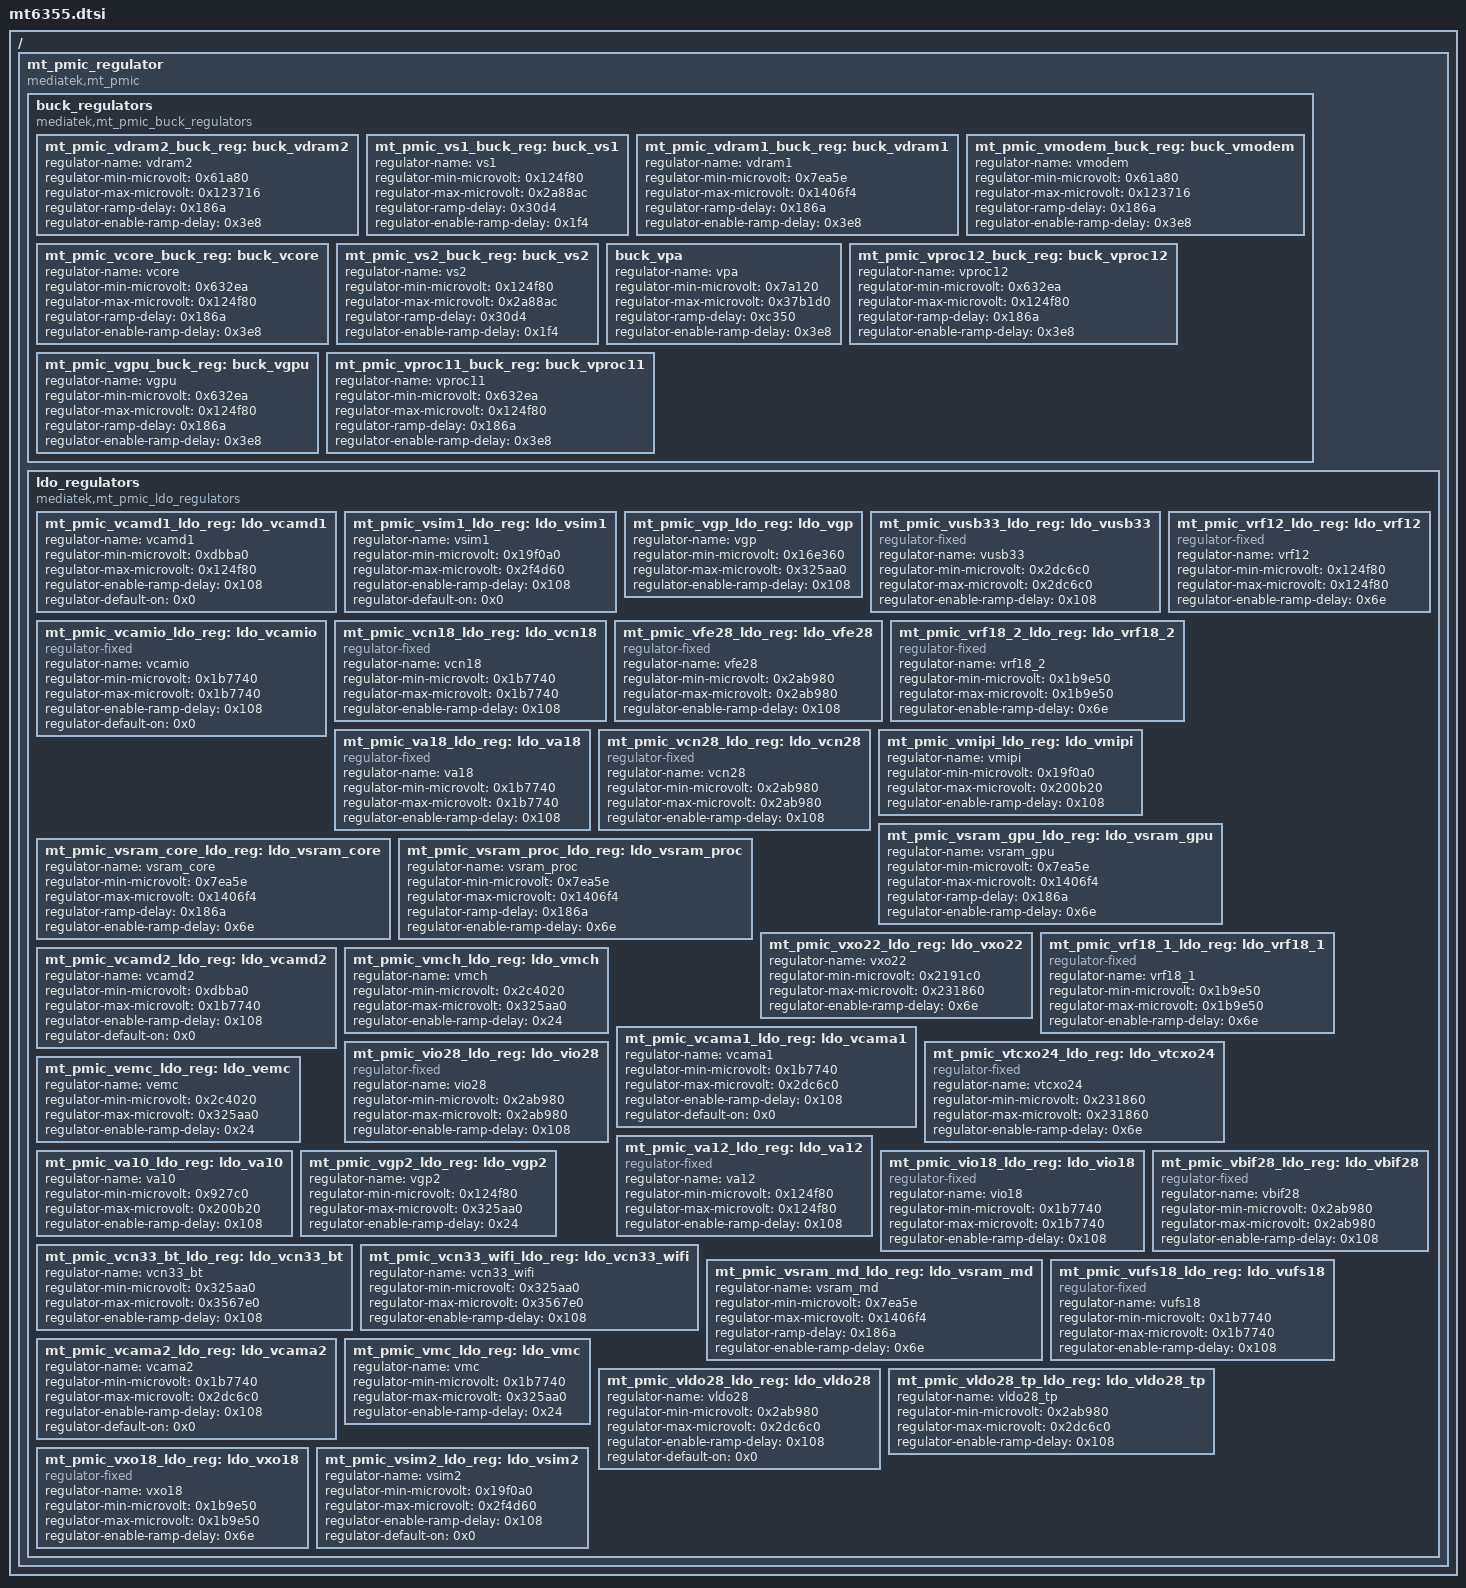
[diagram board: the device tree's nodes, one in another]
/*
 * Copyright (C) 2016 MediaTek Inc.
 *
 * This program is free software; you can redistribute it and/or modify
 * it under the terms of the GNU General Public License version 2 as
 * published by the Free Software Foundation.
 *
 * This program is distributed in the hope that it will be useful,
 * but WITHOUT ANY WARRANTY; without even the implied warranty of
 * MERCHANTABILITY or FITNESS FOR A PARTICULAR PURPOSE.
 * See http://www.gnu.org/licenses/gpl-2.0.html for more details.
 */

/ {
mt_pmic_regulator {
	compatible = "mediatek,mt_pmic";

	buck_regulators {
		compatible = "mediatek,mt_pmic_buck_regulators";
		mt_pmic_vdram2_buck_reg: buck_vdram2 {
				regulator-name = "vdram2";
				regulator-min-microvolt = <0x61a80>;
				regulator-max-microvolt = <0x123716>;
				regulator-ramp-delay = <0x186a>;
				regulator-enable-ramp-delay = <0x3e8>;
		};
		mt_pmic_vs1_buck_reg: buck_vs1 {
				regulator-name = "vs1";
				regulator-min-microvolt = <0x124f80>;
				regulator-max-microvolt = <0x2a88ac>;
				regulator-ramp-delay = <0x30d4>;
				regulator-enable-ramp-delay = <0x1f4>;
		};
		mt_pmic_vdram1_buck_reg: buck_vdram1 {
				regulator-name = "vdram1";
				regulator-min-microvolt = <0x7ea5e>;
				regulator-max-microvolt = <0x1406f4>;
				regulator-ramp-delay = <0x186a>;
				regulator-enable-ramp-delay = <0x3e8>;
		};
		mt_pmic_vmodem_buck_reg: buck_vmodem {
				regulator-name = "vmodem";
				regulator-min-microvolt = <0x61a80>;
				regulator-max-microvolt = <0x123716>;
				regulator-ramp-delay = <0x186a>;
				regulator-enable-ramp-delay = <0x3e8>;
		};
		mt_pmic_vcore_buck_reg: buck_vcore {
				regulator-name = "vcore";
				regulator-min-microvolt = <0x632ea>;
				regulator-max-microvolt = <0x124f80>;
				regulator-ramp-delay = <0x186a>;
				regulator-enable-ramp-delay = <0x3e8>;
		};
		mt_pmic_vs2_buck_reg: buck_vs2 {
				regulator-name = "vs2";
				regulator-min-microvolt = <0x124f80>;
				regulator-max-microvolt = <0x2a88ac>;
				regulator-ramp-delay = <0x30d4>;
				regulator-enable-ramp-delay = <0x1f4>;
		};
		buck_vpa {
				regulator-name = "vpa";
				regulator-min-microvolt = <0x7a120>;
				regulator-max-microvolt = <0x37b1d0>;
				regulator-ramp-delay = <0xc350>;
				regulator-enable-ramp-delay = <0x3e8>;
		};
		mt_pmic_vproc12_buck_reg: buck_vproc12 {
				regulator-name = "vproc12";
				regulator-min-microvolt = <0x632ea>;
				regulator-max-microvolt = <0x124f80>;
				regulator-ramp-delay = <0x186a>;
				regulator-enable-ramp-delay = <0x3e8>;
		};
		mt_pmic_vgpu_buck_reg: buck_vgpu {
				regulator-name = "vgpu";
				regulator-min-microvolt = <0x632ea>;
				regulator-max-microvolt = <0x124f80>;
				regulator-ramp-delay = <0x186a>;
				regulator-enable-ramp-delay = <0x3e8>;
		};
		mt_pmic_vproc11_buck_reg: buck_vproc11 {
				regulator-name = "vproc11";
				regulator-min-microvolt = <0x632ea>;
				regulator-max-microvolt = <0x124f80>;
				regulator-ramp-delay = <0x186a>;
				regulator-enable-ramp-delay = <0x3e8>;
		};
	};	/* End of buck_regulators */
	ldo_regulators {
		compatible = "mediatek,mt_pmic_ldo_regulators";
		mt_pmic_vcamd1_ldo_reg: ldo_vcamd1 {
				regulator-name = "vcamd1";
				regulator-min-microvolt = <0xdbba0>;
				regulator-max-microvolt = <0x124f80>;
				regulator-enable-ramp-delay = <0x108>;
				regulator-default-on = <0x0>;
				status = "okay";
				linux,phandle = <0x55>;
				phandle = <0x55>;
		};
		mt_pmic_vsim1_ldo_reg: ldo_vsim1 {
				regulator-name = "vsim1";
				regulator-min-microvolt = <0x19f0a0>;
				regulator-max-microvolt = <0x2f4d60>;
				regulator-enable-ramp-delay = <0x108>;
				regulator-default-on = <0x0>;
				status = "okay";
		};
		mt_pmic_vgp_ldo_reg: ldo_vgp {
				regulator-name = "vgp";
				regulator-min-microvolt = <0x16e360>;
				regulator-max-microvolt = <0x325aa0>;
				regulator-enable-ramp-delay = <0x108>;
		};
		mt_pmic_vusb33_ldo_reg: ldo_vusb33 {
				compatible = "regulator-fixed";
				regulator-name = "vusb33";
				regulator-min-microvolt = <0x2dc6c0>;
				regulator-max-microvolt = <0x2dc6c0>;
				regulator-enable-ramp-delay = <0x108>;
		};
		mt_pmic_vrf12_ldo_reg: ldo_vrf12 {
				compatible = "regulator-fixed";
				regulator-name = "vrf12";
				regulator-min-microvolt = <0x124f80>;
				regulator-max-microvolt = <0x124f80>;
				regulator-enable-ramp-delay = <0x6e>;
		};
		mt_pmic_vcamio_ldo_reg: ldo_vcamio {
				compatible = "regulator-fixed";
				regulator-name = "vcamio";
				regulator-min-microvolt = <0x1b7740>;
				regulator-max-microvolt = <0x1b7740>;
				regulator-enable-ramp-delay = <0x108>;
				regulator-default-on = <0x0>;
				status = "okay";
				linux,phandle = <0x56>;
				phandle = <0x56>;
		};
		mt_pmic_vcn18_ldo_reg: ldo_vcn18 {
				compatible = "regulator-fixed";
				regulator-name = "vcn18";
				regulator-min-microvolt = <0x1b7740>;
				regulator-max-microvolt = <0x1b7740>;
				regulator-enable-ramp-delay = <0x108>;
		};
		mt_pmic_vfe28_ldo_reg: ldo_vfe28 {
				compatible = "regulator-fixed";
				regulator-name = "vfe28";
				regulator-min-microvolt = <0x2ab980>;
				regulator-max-microvolt = <0x2ab980>;
				regulator-enable-ramp-delay = <0x108>;
		};
		mt_pmic_vrf18_2_ldo_reg: ldo_vrf18_2 {
				compatible = "regulator-fixed";
				regulator-name = "vrf18_2";
				regulator-min-microvolt = <0x1b9e50>;
				regulator-max-microvolt = <0x1b9e50>;
				regulator-enable-ramp-delay = <0x6e>;
		};
		mt_pmic_va18_ldo_reg: ldo_va18 {
				compatible = "regulator-fixed";
				regulator-name = "va18";
				regulator-min-microvolt = <0x1b7740>;
				regulator-max-microvolt = <0x1b7740>;
				regulator-enable-ramp-delay = <0x108>;
		};
		mt_pmic_vcn28_ldo_reg: ldo_vcn28 {
				compatible = "regulator-fixed";
				regulator-name = "vcn28";
				regulator-min-microvolt = <0x2ab980>;
				regulator-max-microvolt = <0x2ab980>;
				regulator-enable-ramp-delay = <0x108>;
		};
		mt_pmic_vmipi_ldo_reg: ldo_vmipi {
				regulator-name = "vmipi";
				regulator-min-microvolt = <0x19f0a0>;
				regulator-max-microvolt = <0x200b20>;
				regulator-enable-ramp-delay = <0x108>;
		};
		mt_pmic_vsram_gpu_ldo_reg: ldo_vsram_gpu {
			regulator-name = "vsram_gpu";
			regulator-min-microvolt = <0x7ea5e>;
			regulator-max-microvolt = <0x1406f4>;
			regulator-ramp-delay = <0x186a>;
			regulator-enable-ramp-delay = <0x6e>;
		};
		mt_pmic_vsram_core_ldo_reg: ldo_vsram_core {
				regulator-name = "vsram_core";
				regulator-min-microvolt = <0x7ea5e>;
				regulator-max-microvolt = <0x1406f4>;
				regulator-ramp-delay = <0x186a>;
				regulator-enable-ramp-delay = <0x6e>;
		};
		mt_pmic_vsram_proc_ldo_reg: ldo_vsram_proc {
		regulator-name = "vsram_proc";
				regulator-min-microvolt = <0x7ea5e>;
				regulator-max-microvolt = <0x1406f4>;
				regulator-ramp-delay = <0x186a>;
				regulator-enable-ramp-delay = <0x6e>;
		};
		mt_pmic_vxo22_ldo_reg: ldo_vxo22 {
				regulator-name = "vxo22";
				regulator-min-microvolt = <0x2191c0>;
				regulator-max-microvolt = <0x231860>;
				regulator-enable-ramp-delay = <0x6e>;
		};
		mt_pmic_vrf18_1_ldo_reg: ldo_vrf18_1 {
				compatible = "regulator-fixed";
				regulator-name = "vrf18_1";
				regulator-min-microvolt = <0x1b9e50>;
				regulator-max-microvolt = <0x1b9e50>;
				regulator-enable-ramp-delay = <0x6e>;
		};
		mt_pmic_vcamd2_ldo_reg: ldo_vcamd2 {
				regulator-name = "vcamd2";
				regulator-min-microvolt = <0xdbba0>;
				regulator-max-microvolt = <0x1b7740>;
				regulator-enable-ramp-delay = <0x108>;
				regulator-default-on = <0x0>;
				status = "okay";
				linux,phandle = <0x57>;
				phandle = <0x57>;
		};
		mt_pmic_vmch_ldo_reg: ldo_vmch {
				regulator-name = "vmch";
				regulator-min-microvolt = <0x2c4020>;
				regulator-max-microvolt = <0x325aa0>;
				regulator-enable-ramp-delay = <0x24>;
				linux,phandle = <0xc>;
				phandle = <0xc>;
		};
		mt_pmic_vcama1_ldo_reg: ldo_vcama1 {
				regulator-name = "vcama1";
				regulator-min-microvolt = <0x1b7740>;
				regulator-max-microvolt = <0x2dc6c0>;
				regulator-enable-ramp-delay = <0x108>;
				regulator-default-on = <0x0>;
				status = "okay";
				linux,phandle = <0x54>;
				phandle = <0x54>;
		};
		mt_pmic_vtcxo24_ldo_reg: ldo_vtcxo24 {
				compatible = "regulator-fixed";
				regulator-name = "vtcxo24";
				regulator-min-microvolt = <0x231860>;
				regulator-max-microvolt = <0x231860>;
				regulator-enable-ramp-delay = <0x6e>;
		};
		mt_pmic_vio28_ldo_reg: ldo_vio28 {
				compatible = "regulator-fixed";
				regulator-name = "vio28";
				regulator-min-microvolt = <0x2ab980>;
				regulator-max-microvolt = <0x2ab980>;
				regulator-enable-ramp-delay = <0x108>;
		};
		mt_pmic_vemc_ldo_reg: ldo_vemc {
				regulator-name = "vemc";
				regulator-min-microvolt = <0x2c4020>;
				regulator-max-microvolt = <0x325aa0>;
				regulator-enable-ramp-delay = <0x24>;
				linux,phandle = <0x5>;
				phandle = <0x5>;
		};
		mt_pmic_va12_ldo_reg: ldo_va12 {
				compatible = "regulator-fixed";
				regulator-name = "va12";
				regulator-min-microvolt = <0x124f80>;
				regulator-max-microvolt = <0x124f80>;
				regulator-enable-ramp-delay = <0x108>;
		};
		mt_pmic_va10_ldo_reg: ldo_va10 {
				regulator-name = "va10";
				regulator-min-microvolt = <0x927c0>;
				regulator-max-microvolt = <0x200b20>;
				regulator-enable-ramp-delay = <0x108>;
		};
		mt_pmic_vgp2_ldo_reg: ldo_vgp2 {
				regulator-name = "vgp2";
				regulator-min-microvolt = <0x124f80>;
				regulator-max-microvolt = <0x325aa0>;
				regulator-enable-ramp-delay = <0x24>;
		};
		mt_pmic_vio18_ldo_reg: ldo_vio18 {
				compatible = "regulator-fixed";
				regulator-name = "vio18";
				regulator-min-microvolt = <0x1b7740>;
				regulator-max-microvolt = <0x1b7740>;
				regulator-enable-ramp-delay = <0x108>;
		};
		mt_pmic_vcn33_bt_ldo_reg: ldo_vcn33_bt {
				regulator-name = "vcn33_bt";
				regulator-min-microvolt = <0x325aa0>;
				regulator-max-microvolt = <0x3567e0>;
				regulator-enable-ramp-delay = <0x108>;
		};
		mt_pmic_vcn33_wifi_ldo_reg: ldo_vcn33_wifi {
				regulator-name = "vcn33_wifi";
				regulator-min-microvolt = <0x325aa0>;
				regulator-max-microvolt = <0x3567e0>;
				regulator-enable-ramp-delay = <0x108>;
		};
		mt_pmic_vsram_md_ldo_reg: ldo_vsram_md {
				regulator-name = "vsram_md";
				regulator-min-microvolt = <0x7ea5e>;
				regulator-max-microvolt = <0x1406f4>;
				regulator-ramp-delay = <0x186a>;
				regulator-enable-ramp-delay = <0x6e>;
		};
		mt_pmic_vbif28_ldo_reg: ldo_vbif28 {
				compatible = "regulator-fixed";
				regulator-name = "vbif28";
				regulator-min-microvolt = <0x2ab980>;
				regulator-max-microvolt = <0x2ab980>;
				regulator-enable-ramp-delay = <0x108>;
		};
		mt_pmic_vufs18_ldo_reg: ldo_vufs18 {
				compatible = "regulator-fixed";
				regulator-name = "vufs18";
				regulator-min-microvolt = <0x1b7740>;
				regulator-max-microvolt = <0x1b7740>;
				regulator-enable-ramp-delay = <0x108>;
		};
		mt_pmic_vcama2_ldo_reg: ldo_vcama2 {
				regulator-name = "vcama2";
				regulator-min-microvolt = <0x1b7740>;
				regulator-max-microvolt = <0x2dc6c0>;
				regulator-enable-ramp-delay = <0x108>;
				regulator-default-on = <0x0>;
				status = "okay";
				linux,phandle = <0x7c>;
				phandle = <0x7c>;
		};
		mt_pmic_vmc_ldo_reg: ldo_vmc {
				regulator-name = "vmc";
				regulator-min-microvolt = <0x1b7740>;
				regulator-max-microvolt = <0x325aa0>;
				regulator-enable-ramp-delay = <0x24>;
				linux,phandle = <0xd>;
				phandle = <0xd>;
		};
		mt_pmic_vldo28_ldo_reg: ldo_vldo28 {
				regulator-name = "vldo28";
				regulator-min-microvolt = <0x2ab980>;
				regulator-max-microvolt = <0x2dc6c0>;
				regulator-enable-ramp-delay = <0x108>;
				regulator-default-on = <0x0>;
				status = "okay";
				linux,phandle = <0x27>;
				phandle = <0x27>;
		};
		mt_pmic_vldo28_tp_ldo_reg: ldo_vldo28_tp {
				regulator-name = "vldo28_tp";
				regulator-min-microvolt = <0x2ab980>;
				regulator-max-microvolt = <0x2dc6c0>;
				regulator-enable-ramp-delay = <0x108>;
		};
		mt_pmic_vxo18_ldo_reg: ldo_vxo18 {
				compatible = "regulator-fixed";
				regulator-name = "vxo18";
				regulator-min-microvolt = <0x1b9e50>;
				regulator-max-microvolt = <0x1b9e50>;
				regulator-enable-ramp-delay = <0x6e>;
		};
		mt_pmic_vsim2_ldo_reg: ldo_vsim2 {
				regulator-name = "vsim2";
				regulator-min-microvolt = <0x19f0a0>;
				regulator-max-microvolt = <0x2f4d60>;
				regulator-enable-ramp-delay = <0x108>;
				regulator-default-on = <0x0>;
				status = "okay";
		};
	};	/* End of ldo_regulators */
};/* End of mt_pmic_regulator */
};
